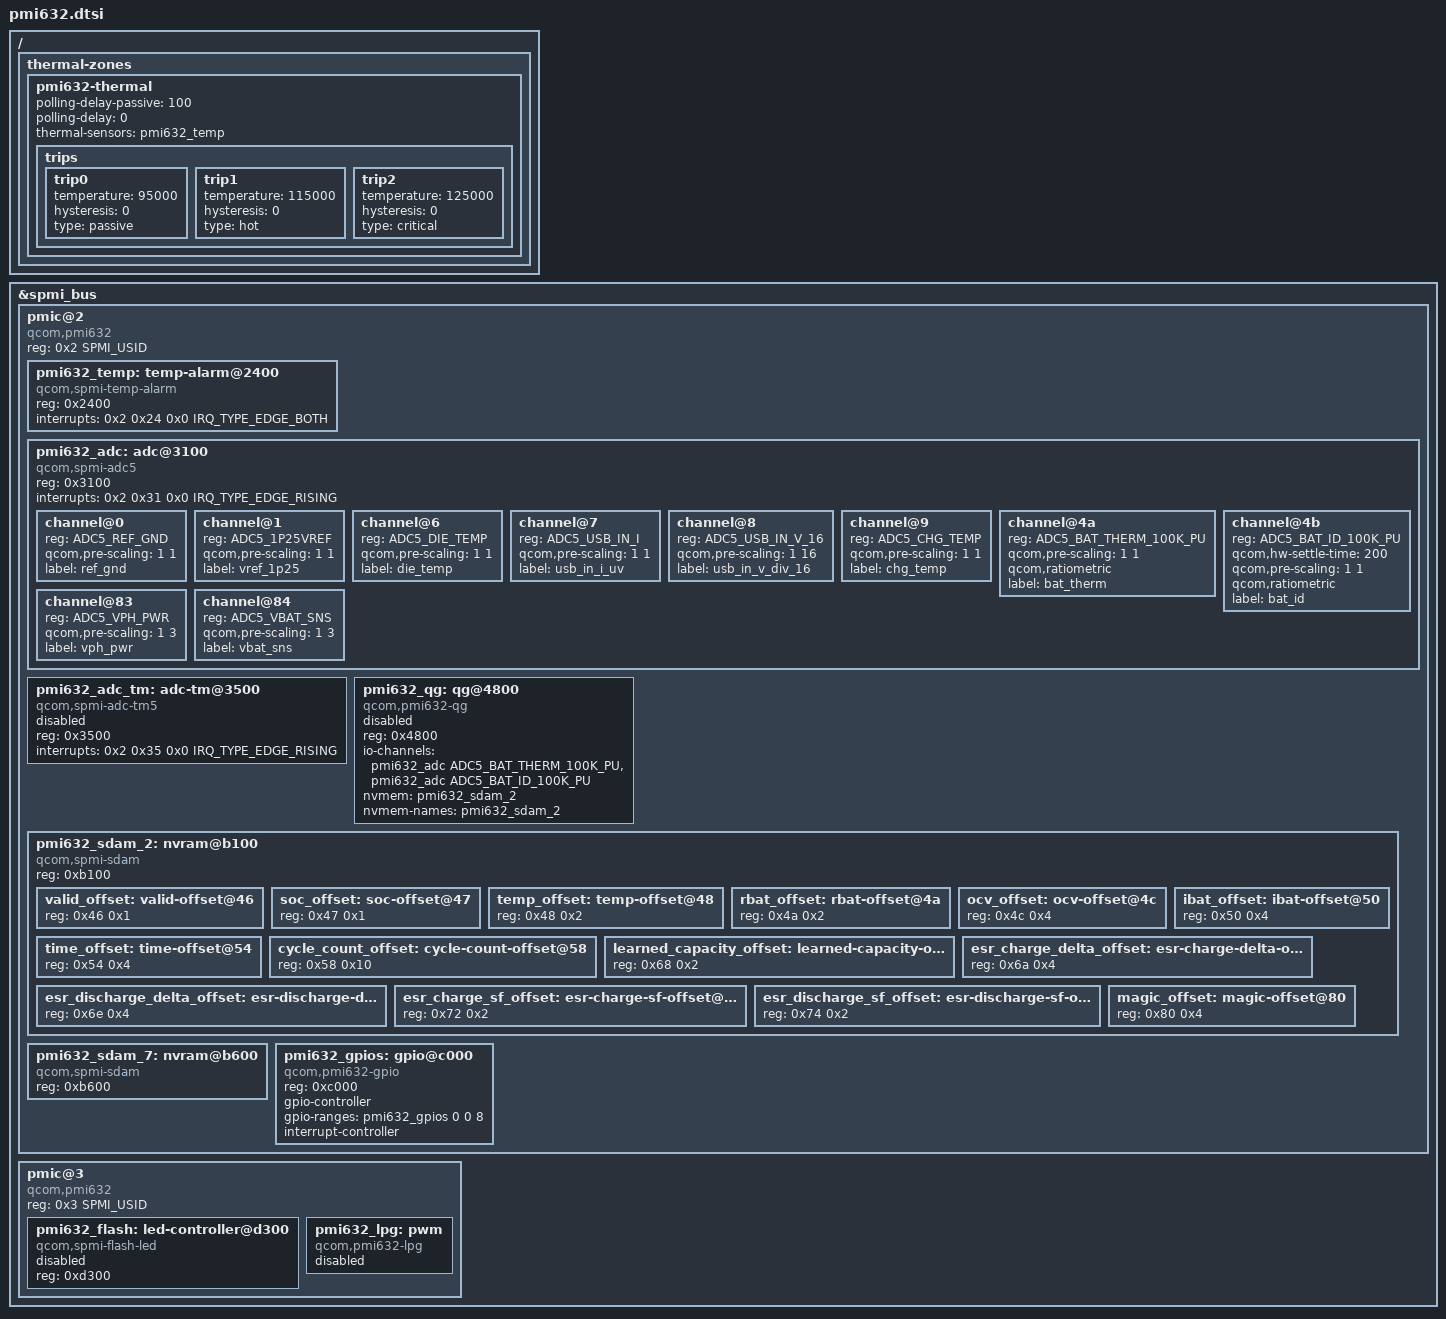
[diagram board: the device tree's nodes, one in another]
// SPDX-License-Identifier: BSD-3-Clause
/*
 * Copyright (C) 2023 Luca Weiss <luca@z3ntu.xyz>
 */

#include <dt-bindings/iio/qcom,spmi-vadc.h>
#include <dt-bindings/interrupt-controller/irq.h>
#include <dt-bindings/spmi/spmi.h>

/ {
	thermal-zones {
		pmi632-thermal {
			polling-delay-passive = <100>;
			polling-delay = <0>;

			thermal-sensors = <&pmi632_temp>;

			trips {
				trip0 {
					temperature = <95000>;
					hysteresis = <0>;
					type = "passive";
				};

				trip1 {
					temperature = <115000>;
					hysteresis = <0>;
					type = "hot";
				};

				trip2 {
					temperature = <125000>;
					hysteresis = <0>;
					type = "critical";
				};
			};
		};
	};
};

&spmi_bus {
	pmic@2 {
		compatible = "qcom,pmi632", "qcom,spmi-pmic";
		reg = <0x2 SPMI_USID>;
		#address-cells = <1>;
		#size-cells = <0>;

		pmi632_temp: temp-alarm@2400 {
			compatible = "qcom,spmi-temp-alarm";
			reg = <0x2400>;
			interrupts = <0x2 0x24 0x0 IRQ_TYPE_EDGE_BOTH>;
			#thermal-sensor-cells = <0>;
		};

		pmi632_adc: adc@3100 {
			compatible = "qcom,spmi-adc5";
			reg = <0x3100>;
			#address-cells = <1>;
			#size-cells = <0>;
			#io-channel-cells = <1>;
			interrupts = <0x2 0x31 0x0 IRQ_TYPE_EDGE_RISING>;

			channel@0 {
				reg = <ADC5_REF_GND>;
				qcom,pre-scaling = <1 1>;
				label = "ref_gnd";
			};

			channel@1 {
				reg = <ADC5_1P25VREF>;
				qcom,pre-scaling = <1 1>;
				label = "vref_1p25";
			};

			channel@6 {
				reg = <ADC5_DIE_TEMP>;
				qcom,pre-scaling = <1 1>;
				label = "die_temp";
			};

			channel@7 {
				reg = <ADC5_USB_IN_I>;
				qcom,pre-scaling = <1 1>;
				label = "usb_in_i_uv";
			};

			channel@8 {
				reg = <ADC5_USB_IN_V_16>;
				qcom,pre-scaling = <1 16>;
				label = "usb_in_v_div_16";
			};

			channel@9 {
				reg = <ADC5_CHG_TEMP>;
				qcom,pre-scaling = <1 1>;
				label = "chg_temp";
			};

			channel@4a {
				reg = <ADC5_BAT_THERM_100K_PU>;
				qcom,pre-scaling = <1 1>;
				qcom,ratiometric;
				label = "bat_therm";
			};

			channel@4b {
				reg = <ADC5_BAT_ID_100K_PU>;
				qcom,hw-settle-time = <200>;
				qcom,pre-scaling = <1 1>;
				qcom,ratiometric;
				label = "bat_id";
			};

			channel@83 {
				reg = <ADC5_VPH_PWR>;
				qcom,pre-scaling = <1 3>;
				label = "vph_pwr";
			};

			channel@84 {
				reg = <ADC5_VBAT_SNS>;
				qcom,pre-scaling = <1 3>;
				label = "vbat_sns";
			};
		};

		pmi632_adc_tm: adc-tm@3500 {
			compatible = "qcom,spmi-adc-tm5";
			reg = <0x3500>;
			interrupts = <0x2 0x35 0x0 IRQ_TYPE_EDGE_RISING>;
			#thermal-sensor-cells = <1>;
			#address-cells = <1>;
			#size-cells = <0>;
			status = "disabled";
		};

		pmi632_qg: qg@4800 {
			compatible = "qcom,pmi632-qg";
			reg = <0x4800>;
			io-channels = <&pmi632_adc ADC5_BAT_THERM_100K_PU>,
				      <&pmi632_adc ADC5_BAT_ID_100K_PU>;
			io-channel-names = "bat_therm", "bat_id";
			nvmem = <&pmi632_sdam_2>;
			nvmem-names = "pmi632_sdam_2";
			status = "disabled";
		};

		pmi632_sdam_2: nvram@b100 {
			compatible = "qcom,spmi-sdam";
			reg = <0xb100>;
			#address-cells = <1>;
			#size-cells = <1>;
			ranges = <0 0xb100 0x100>;

			/* The following values are taken from the SDAM offsets
			 * in qg-regs.h.
			 * Do we need these cells or should we use the
			 * complete nvmem device?
			 */
			valid_offset: valid-offset@46 {
				reg = <0x46 0x1>;
			};

			soc_offset: soc-offset@47 {
				reg = <0x47 0x1>;
			};

			temp_offset: temp-offset@48 {
				reg = <0x48 0x2>;
			};

			rbat_offset: rbat-offset@4a {
				reg = <0x4a 0x2>;
			};

			ocv_offset: ocv-offset@4c {
				reg = <0x4c 0x4>;
			};

			ibat_offset: ibat-offset@50 {
				reg = <0x50 0x4>;
			};

			time_offset: time-offset@54 {
				reg = <0x54 0x4>;
			};

			cycle_count_offset: cycle-count-offset@58 {
				reg = <0x58 0x10>;
			};

			learned_capacity_offset: learned-capacity-offset@68 {
				reg = <0x68 0x2>;
			};

			esr_charge_delta_offset: esr-charge-delta-offset@6a {
				reg = <0x6a 0x4>;
			};

			esr_discharge_delta_offset: esr-discharge-delta-offset@6e {
				reg = <0x6e 0x4>;
			};

			esr_charge_sf_offset: esr-charge-sf-offset@72 {
				reg = <0x72 0x2>;
			};

			esr_discharge_sf_offset: esr-discharge-sf-offset@74 {
				reg = <0x74 0x2>;
			};

			magic_offset: magic-offset@80 {
				reg = <0x80 0x4>;
			};
		};

		pmi632_sdam_7: nvram@b600 {
			compatible = "qcom,spmi-sdam";
			reg = <0xb600>;
			#address-cells = <1>;
			#size-cells = <1>;
			ranges = <0 0xb600 0x100>;
		};

		pmi632_gpios: gpio@c000 {
			compatible = "qcom,pmi632-gpio", "qcom,spmi-gpio";
			reg = <0xc000>;
			gpio-controller;
			gpio-ranges = <&pmi632_gpios 0 0 8>;
			#gpio-cells = <2>;
			interrupt-controller;
			#interrupt-cells = <2>;
		};
	};

	pmic@3 {
		compatible = "qcom,pmi632", "qcom,spmi-pmic";
		reg = <0x3 SPMI_USID>;
		#address-cells = <1>;
		#size-cells = <0>;
 
		pmi632_flash: led-controller@d300 {
			compatible = "qcom,spmi-flash-led";
			reg = <0xd300>;
			status = "disabled";
		};

		pmi632_lpg: pwm {
			compatible = "qcom,pmi632-lpg";

			#address-cells = <1>;
			#size-cells = <0>;
			#pwm-cells = <2>;

			status = "disabled";
		};
	};
};
